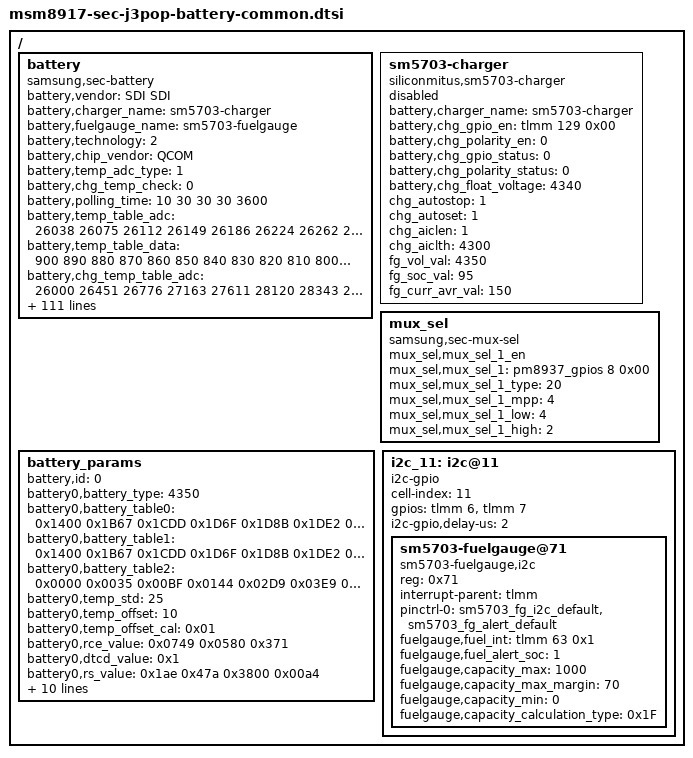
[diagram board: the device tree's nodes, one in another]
/* Copyright (c) 2015, The Linux Foundation. All rights reserved.
 *
 * This program is free software; you can redistribute it and/or modify
 * it under the terms of the GNU General Public License version 2 and
 * only version 2 as published by the Free Software Foundation.
 *
 * This program is distributed in the hope that it will be useful,
 * but WITHOUT ANY WARRANTY; without even the implied warranty of
 * MERCHANTABILITY or FITNESS FOR A PARTICULAR PURPOSE.  See the
 * GNU General Public License for more details.
 */

/ {
	battery {
		status = "okay";
		compatible = "samsung,sec-battery";
		battery,vendor = "SDI SDI";
		battery,charger_name = "sm5703-charger";
		battery,fuelgauge_name = "sm5703-fuelgauge";
		battery,technology = <2>; /* POWER_SUPPLY_TECHNOLOGY_LION */

		battery,chip_vendor = "QCOM";
		battery,temp_adc_type = <1>; /* SEC_BATTERY_ADC_TYPE_AP */

		battery,chg_temp_check = <0>;

		battery,polling_time = <10 30 30 30 3600>;

		battery,temp_table_adc = <26038 26075 26112 26149 26186 26224 26262 26301 26339 26378
                                          26416 26485 26555 26624 26694 26763 26833 26903 26973 27043
                                          27113 27195 27277 27360 27442 27524 27618 27712 27806 27900
                                          27994 28111 28228 28346 28463 28580 28719 28858 28997 29136
                                          29275 29429 29583 29737 29891 30045 30198 30351 30504 30657
                                          30810 30982 31155 31327 31500 31673 31861 32050 32239 32427
                                          32616 32832 33048 33264 33480 33697 33915 34134 34353 34572
                                          34791 35010 35230 35449 35669 35888 36098 36309 36519 36730
                                          36940 37136 37331 37527 37722 37918 38116 38313 38511 38708
                                          38906 39066 39225 39385 39545 39705 39827 39949 40071 40193
                                          40315 40431 40548 40664 40781 40898 40976 41054 41132 41211
                                          41289>;

		battery,temp_table_data = <900 890 880 870 860 850 840 830 820 810 
                                           800 790 780 770 760 750 740 730 720 710
                                           700 690 680 670 660 650 640 630 620 610
                                           600 590 580 570 560 550 540 530 520 510
                                           500 490 480 470 460 450 440 430 420 410
                                           400 390 380 370 360 350 340 330 320 310
                                           300 290 280 270 260 250 240 230 220 210
                                           200 190 180 170 160 150 140 130 120 110
                                           100  90  80  70  60  50  40  30  20  10
                                             0 (-10) (-20) (-30) (-40) (-50) (-60) (-70) (-80) (-90)
                                           (-100) (-110) (-120) (-130) (-140) (-150) (-160) (-170) (-180) (-190)
                                           (-200)>;

		battery,chg_temp_table_adc = <26000 26451 26776 27163 27611 28120 28343 28498 28725 28968 29223 29475 29512 29847 30172 31107 32031 32999 34092 35083 36181 37166 38088 38675 39491 40103 40760 41265>;

		battery,chg_temp_table_data = <900 800 750 700 650 600 580 570 550 530 510 500 490 470 450 400 350 300 250 200 150 100 50 0 (-50) (-100) (-150) (-200)>;

		battery,siop_input_limit_current = <1000>;
		battery,siop_charging_limit_current = <2100>;
		battery,siop_hv_input_limit_current = <700>;
		battery,siop_hv_charging_limit_current = <1000>;

		battery,siop_wireless_input_limit_current = <700>;
		battery,siop_wireless_charging_limit_current = <600>;
		battery,siop_hv_wireless_input_limit_current = <500>;
		battery,siop_hv_wireless_charging_limit_current = <1000>;
		battery,siop_call_cv_current = <500>;
		battery,siop_call_cc_current = <500>;

		battery,input_current_limit = <1350 500 500 1350 500 900 1000 500 500 1000 820 1350 1350 500 1000 300 700 1000 1000 300 80 500 1000 1000 1000 1000 900 820 820 500 1000 1000 820 820 820 820 820 820>;
		battery,fast_charging_current = <2100 0 500 2100 500 1200 1000 500 0 1200 1000 2100 2100 0 1300 300 700 1300 1500 300 80 0 3250 1000 3250 1400 1200 1000 1000 0 0 1000 1000 1000 1000 1000 1000 1000>;
		battery,full_check_current_1st = <175 0 175 175 175 175 175 175 0 175 175 175 175 0 175 175 175 175 175 175 175 0 175 175 175 175 175 175 175 0 0 175 175 175 175 175 175 175>;
		battery,full_check_current_2nd = <100 0 100 100 100 100 100 100 0 100 100 100 100 0 100 100 100 100 100 100 100 0 100 100 100 100 100 100 100 0 0 100 100 100 100 100 100 100>;

		battery,step_charging_type = <0x1>; /* STEP_CHARGING_CONDITION_VOLTAGE */
		battery,step_charging_condtion = <4100 4400>;
		battery,step_charging_current = <3960 3300>; /* 1.2C  1C */

		battery,adc_check_count = <5>;

		battery,cable_check_type = <4>; /* SEC_BATTERY_CABLE_CHECK_PSY */
		battery,cable_source_type = <3>; /* SEC_BATTERY_CABLE_SOURCE_EXTERNAL */
		battery,event_waiting_time = <600>;
		battery,polling_type = <1>; /* SEC_BATTERY_MONITOR_ALARM */
		battery,monitor_initial_count = <3>;

		battery,battery_check_type = <0>; /* SEC_BATTERY_CHECK_NONE */
		battery,check_count = <2>;
		battery,batt_channel = <2>;
		battery,check_adc_max = <27000>;
		battery,check_adc_min = <23000>;

		battery,ovp_uvlo_check_type = <3>; /* SEC_BATTERY_OVP_UVLO_CHGPOLLING */

		battery,thermal_source = <2>; /* SEC_BATTERY_THERMAL_SOURCE_ADC */
		battery,chg_thermal_source = <0>;
		battery,mux_channel = <4>;

		battery,temp_check_type = <2>; /* SEC_BATTERY_TEMP_CHECK_TEMP */
		battery,temp_check_count = <1>;
		battery,temp_highlimit_threshold_event = <800>;
		battery,temp_highlimit_recovery_event = <750>;
		battery,temp_high_threshold_event = <550>;
		battery,temp_high_recovery_event = <500>;
		battery,temp_low_threshold_event = <(-50)>;
		battery,temp_low_recovery_event = <0>;
		battery,temp_highlimit_threshold_normal = <800>;
		battery,temp_highlimit_recovery_normal = <750>;
		battery,temp_high_threshold_normal = <550>;
		battery,temp_high_recovery_normal = <500>;
		battery,temp_low_threshold_normal = <(-50)>;
		battery,temp_low_recovery_normal = <0>;
		battery,temp_highlimit_threshold_lpm = <800>;
		battery,temp_highlimit_recovery_lpm = <750>;
		battery,temp_high_threshold_lpm = <550>;
		battery,temp_high_recovery_lpm = <500>;
		battery,temp_low_threshold_lpm = <(-50)>;
		battery,temp_low_recovery_lpm = <0>;
		battery,full_check_type = <2>; /* SEC_BATTERY_FULLCHARGED_FG_CURRENT */
		battery,full_check_type_2nd = <2>; /* SEC_BATTERY_FULLCHARGED_FG_CURRENT */
		battery,full_check_count = <1>;
		battery,chg_gpio_full_check = <0>;
		battery,chg_polarity_full_check = <1>;

		battery,chg_high_temp_1st = <465>;
		battery,chg_high_temp_2nd = <465>;
		battery,chg_high_temp_recovery = <455>;
		battery,chg_charging_limit_current = <1400>;
		battery,chg_charging_limit_current_2nd = <1400>;
		battery,chg_skip_check_capacity = <10>;
		battery,chg_skip_check_time = <600>;

		/* SEC_BATTERY_FULL_CONDITION_SOC |
		   SEC_BATTERY_FULL_CONDITION_NOTIMEFULL |
		   SEC_BATTERY_FULL_CONDITION_VCELL */
		battery,full_condition_type = <13>;
		battery,full_condition_soc = <93>;
		battery,full_condition_vcell = <4240>;

		battery,recharge_check_count = <1>;
		battery,recharge_condition_type = <4>; /* SEC_BATTERY_RECHARGE_CONDITION_VCELL */
		battery,recharge_condition_soc = <98>;
		battery,recharge_condition_vcell = <4290>;

		//battery,self_discharging_en;
		battery,self_discharging_type = <2>;	/* SEC_BAT_SELF_DISCHARGING_BY_CHG */
		//battery,factory_discharging = <&expander_gpios 13 0x00>;

		battery,force_discharging_limit = <600>;
		battery,force_discharging_recov = <550>;
		battery,self_discharging_voltage_limit = <4250>;
		battery,discharging_adc_max = <29864>;
		battery,discharging_adc_min = <25768>;
		battery,discharging_ntc_limit = <2750>;

		battery,charging_total_time = <21600>;
		battery,recharging_total_time = <5400>;
		battery,charging_reset_time = <0>;

		battery,swelling_high_temp_block = <450>;
		battery,swelling_high_temp_recov = <400>;
		battery,swelling_low_temp_block = <100>;
		battery,swelling_low_temp_recov = <150>;
		//battery,swelling_chg_current = <1500>;
		battery,swelling_high_temp_current = <1820>;
		battery,swelling_low_temp_current = <1300>;
		battery,swelling_low_temp_additional = <50>;
		battery,swelling_low_temp_additional_current = <500>;
		battery,swelling_low_temp_topoff = <100>;
		battery,swelling_high_temp_topoff = <100>;
		battery,swelling_drop_float_voltage = <4210>;
		battery,swelling_high_rechg_voltage = <4150>;
		battery,swelling_low_rechg_voltage = <4050>;
		battery,swelling_block_time = <600>;

		battery,self_discharging_temp_block = <600>;
		battery,self_discharging_volt_block = <4250>;
		battery,self_discharging_temp_recov = <550>;
		battery,self_discharging_temp_pollingtime = <400>;

		battery,chg_float_voltage = <4340>;

		qcom,sec-battery-vadc = <&pm8937_vadc>;
	};

	sm5703-charger {
		status = "disable";
		compatible = "siliconmitus,sm5703-charger";

		/* Charger */
		battery,charger_name = "sm5703-charger";
		battery,chg_gpio_en = <&tlmm 129 0x00>;
		battery,chg_polarity_en = <0>;
		battery,chg_gpio_status = <0>;
		battery,chg_polarity_status = <0>;
		battery,chg_float_voltage = <4340>;
		chg_autostop = <1>;
		chg_autoset = <1>;
		chg_aiclen = <1>;
		chg_aiclth = <4300>;
		fg_vol_val = <4350>;
		fg_soc_val = <95>;
		fg_curr_avr_val = <150>;
	};

	mux_sel {
		compatible = "samsung,sec-mux-sel";
		mux_sel,mux_sel_1_en;
		mux_sel,mux_sel_1 = <&pm8937_gpios 8 0x00>;
		mux_sel,mux_sel_1_type = <20>; /* BATT_THM_MUX_SEL | AP_THM_MUX_SEL */
		mux_sel,mux_sel_1_mpp = <4>; /* SEC_MPP4_MUX_SEL */
		mux_sel,mux_sel_1_low = <4>; /* SEC_MUX_SEL_AP_THM */
		mux_sel,mux_sel_1_high = <2>; /* SEC_MUX_SEL_BATT_THM */
	};

	battery_params {
		battery,id = <0>; /* -1 means auto, detected by F/G */
		battery0,battery_type = <4350>; /* 4200 4350 4400 */
		battery0,battery_table0 = <0x1400 0x1B67 0x1CDD 0x1D6F 0x1D8B 0x1DE2 0x1E32 0x1E63 0x1EAB 0x1EDF 0x1F06 0x1F54 0x1FC5 0x20A0 0x2261 0x2399>;
		battery0,battery_table1 = <0x1400 0x1B67 0x1CDD 0x1D6F 0x1D8B 0x1DE2 0x1E32 0x1E63 0x1EAB 0x1EDF 0x1F06 0x1F54 0x1FC5 0x20A0 0x2261 0x2399>;
		battery0,battery_table2 = <0x0000 0x0035 0x00BF 0x0144 0x02D9 0x03E9 0x0602 0x0821 0x0A3B 0x0B4B 0x0BD5 0x0C5A 0x0DEF 0x1093 0x14CC 0x14DC>;
		battery0,temp_std = <25>;
		battery0,temp_offset = <10>;
		battery0,temp_offset_cal = <0x01>;
		battery0,rce_value = <0x0749 0x0580 0x371>;
		battery0,dtcd_value = <0x1>;
		battery0,rs_value = <0x1ae 0x47a 0x3800 0x00a4>; /*rs mix_factor max min*/
		battery0,vit_period = <0x3506>;
		battery0,mix_value = <0x0503 0x0004>; /*mix_rate init_blank*/
		battery0,topoff_soc = <0x0 0x5>; /*enable soc*/
		battery0,tem_poff = <3400 50 3350 50>;
		battery0,charge_offset_cal = <0x03>;
		battery0,volt_cal = <0x809E>;
		battery0,curr_cal = <0x7485>;
		battery0,ext_temp_cal = <0 10 1 1 1 7 1 2>;
		battery0,v_alarm = <3200>;
		battery0,data_ver = <0x01>;
	};

	i2c_11: i2c@11 {
		cell-index = <11>;
		compatible = "i2c-gpio";
		gpios = <&tlmm 6 0	/* sda */
			&tlmm 7 0	/* scl */
			>;
		i2c-gpio,delay-us = <2>;
		#address-cells = <1>;
		#size-cells = <0>;

		sm5703-fuelgauge@71{
			status = "okay";
			compatible = "sm5703-fuelgauge,i2c";
			reg = <0x71>;
			interrupt-parent = <&tlmm>;
			pinctrl-names = "default";
			pinctrl-0 = <&sm5703_fg_i2c_default &sm5703_fg_alert_default>;
			fuelgauge,fuel_int = <&tlmm 63 0x1>;
			fuelgauge,fuel_alert_soc = <1>;
			fuelgauge,capacity_max = <1000>;
			fuelgauge,capacity_max_margin = <70>;
			fuelgauge,capacity_min = <0>;
			fuelgauge,capacity_calculation_type = <0x1F>;
		};
	};
};
